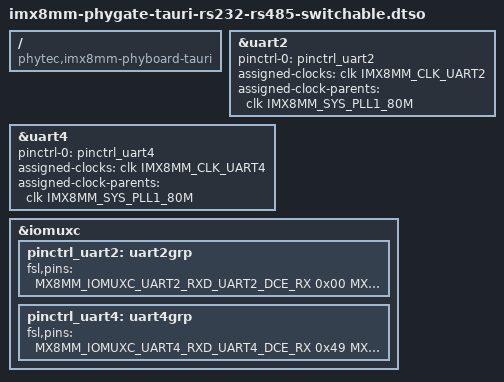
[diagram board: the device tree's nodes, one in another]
// SPDX-License-Identifier: GPL-2.0
/*
* Copyright (C) 2021 PHYTEC Messtechnik GmbH
* Author: Jens Lang <j.lang@phytec.de>
*/

/dts-v1/;
/plugin/;

#include <dt-bindings/clock/imx8mm-clock.h>
#include "../imx8mm-pinfunc.h"

/ {
	compatible = "phytec,imx8mm-phyboard-tauri";
};

/* UART2 * RS232  */
&uart2 {
	#address-cells = <1>;
	#size-cells = <0>;

	pinctrl-names = "default";
	pinctrl-0 = <&pinctrl_uart2>;
	assigned-clocks = <&clk IMX8MM_CLK_UART2>;
	assigned-clock-parents = <&clk IMX8MM_SYS_PLL1_80M>;
	status = "okay";
};

/* UART4 * RS232/RS485 switchable */
&uart4 {
	#address-cells = <1>;
	#size-cells = <0>;

	pinctrl-names = "default";
	pinctrl-0 = <&pinctrl_uart4>;
	assigned-clocks = <&clk IMX8MM_CLK_UART4>;
	assigned-clock-parents = <&clk IMX8MM_SYS_PLL1_80M>;
	status = "okay";
};

&iomuxc {

	pinctrl_uart2: uart2grp {
		fsl,pins = <
			MX8MM_IOMUXC_UART2_RXD_UART2_DCE_RX	0x00
			MX8MM_IOMUXC_UART2_TXD_UART2_DCE_TX	0x00
		>;
	};

	pinctrl_uart4: uart4grp {
		fsl,pins = <
			MX8MM_IOMUXC_UART4_RXD_UART4_DCE_RX	0x49
			MX8MM_IOMUXC_UART4_TXD_UART4_DCE_TX	0x49
		>;
	};
};
